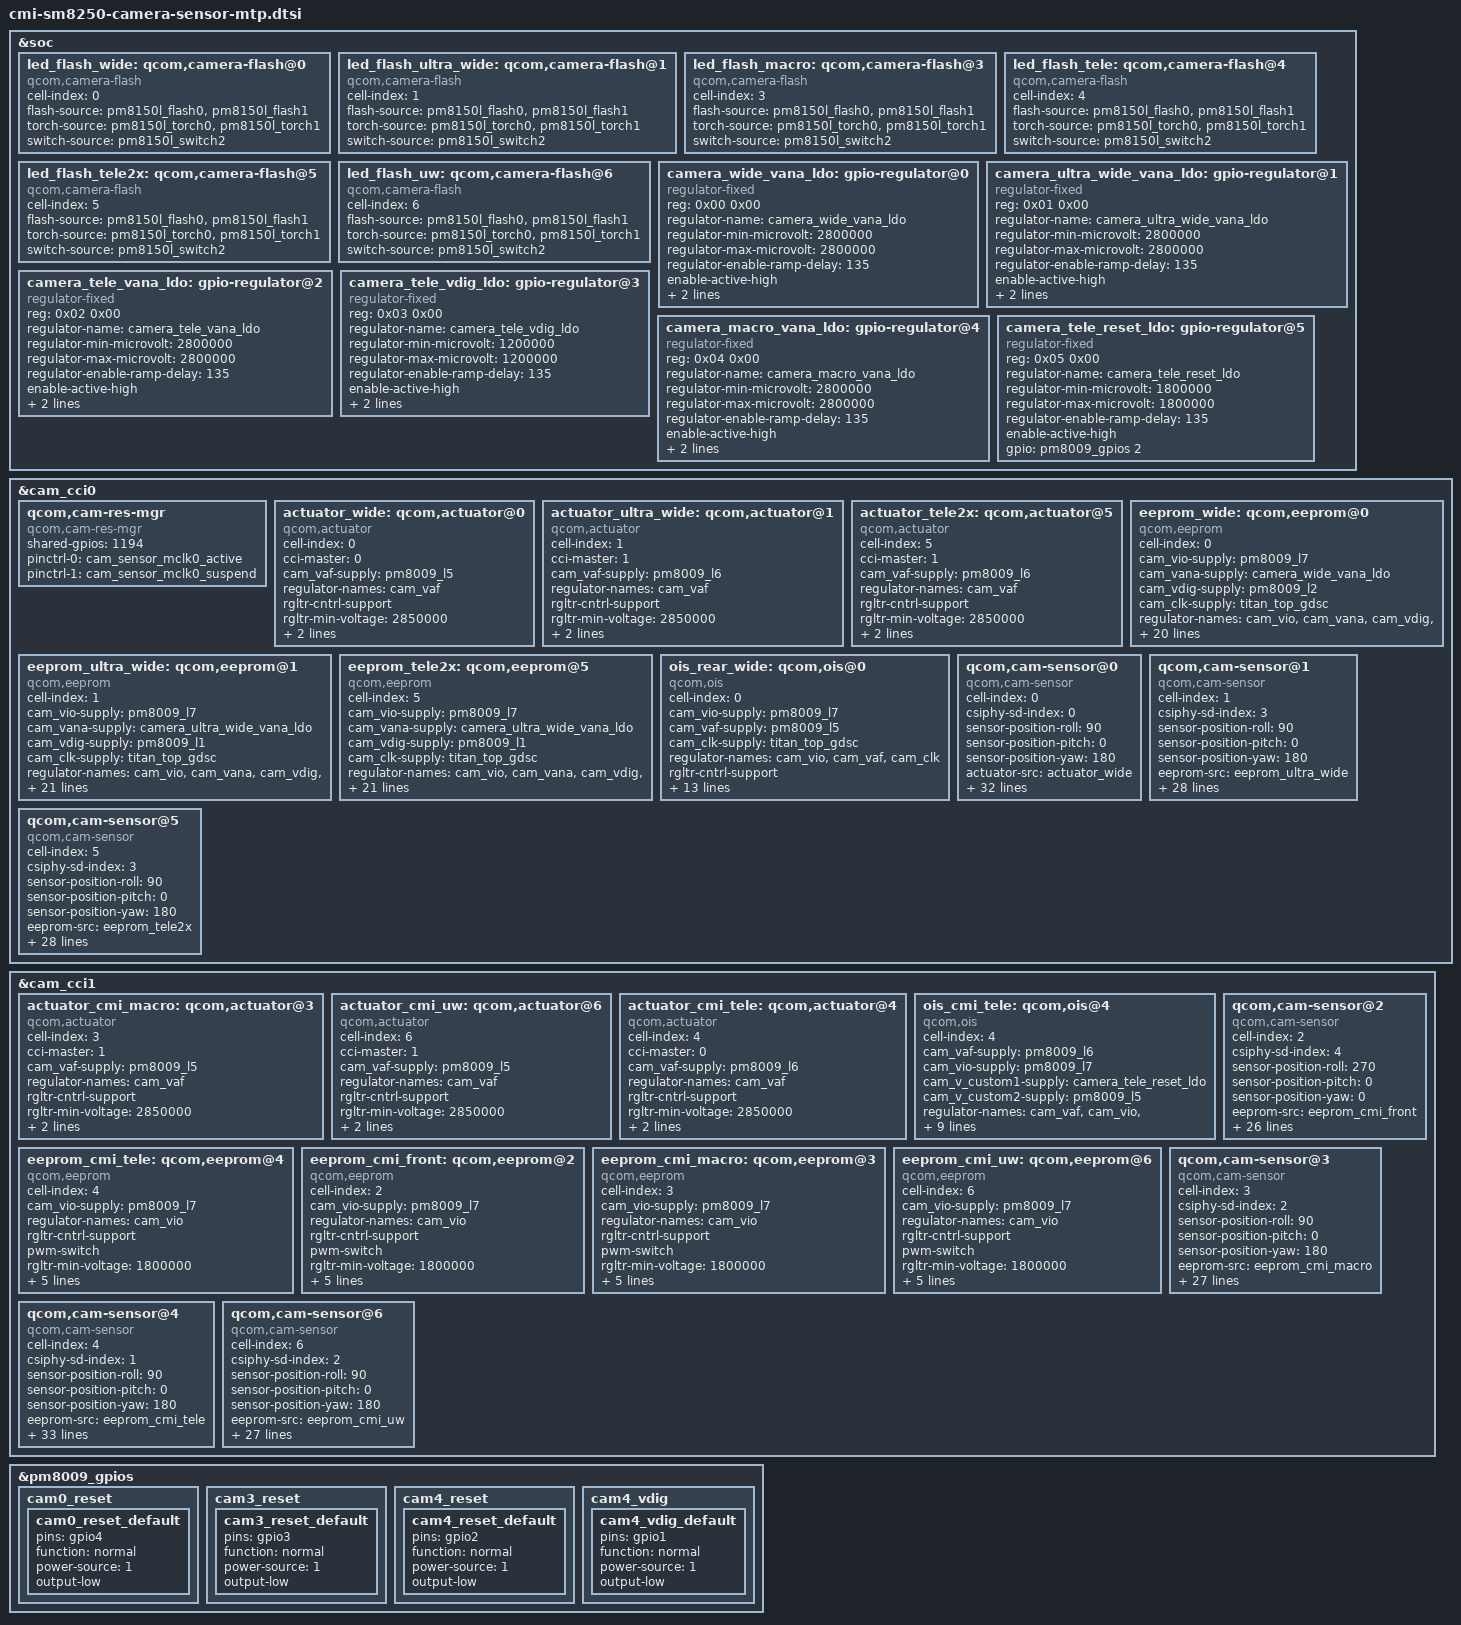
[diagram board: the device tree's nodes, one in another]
&soc {
	led_flash_wide: qcom,camera-flash@0 {
		cell-index = <0>;
		compatible = "qcom,camera-flash";
		flash-source = <&pm8150l_flash0 &pm8150l_flash1>;
		torch-source = <&pm8150l_torch0 &pm8150l_torch1>;
		switch-source = <&pm8150l_switch2>;
		status = "ok";
	};

	led_flash_ultra_wide: qcom,camera-flash@1 {
		cell-index = <1>;
		compatible = "qcom,camera-flash";
		flash-source = <&pm8150l_flash0 &pm8150l_flash1>;
		torch-source = <&pm8150l_torch0 &pm8150l_torch1>;
		switch-source = <&pm8150l_switch2>;
		status = "ok";
	};

	led_flash_macro: qcom,camera-flash@3 {
		cell-index = <3>;
		compatible = "qcom,camera-flash";
		flash-source = <&pm8150l_flash0 &pm8150l_flash1>;
		torch-source = <&pm8150l_torch0 &pm8150l_torch1>;
		switch-source = <&pm8150l_switch2>;
		status = "ok";
	};

	led_flash_tele: qcom,camera-flash@4 {
		cell-index = <4>;
		compatible = "qcom,camera-flash";
		flash-source = <&pm8150l_flash0 &pm8150l_flash1>;
		torch-source = <&pm8150l_torch0 &pm8150l_torch1>;
		switch-source = <&pm8150l_switch2>;
		status = "ok";
	};

	led_flash_tele2x: qcom,camera-flash@5 {
		cell-index = <5>;
		compatible = "qcom,camera-flash";
		flash-source = <&pm8150l_flash0 &pm8150l_flash1>;
		torch-source = <&pm8150l_torch0 &pm8150l_torch1>;
		switch-source = <&pm8150l_switch2>;
		status = "ok";
	};

	led_flash_uw: qcom,camera-flash@6 {
		cell-index = <6>;
		compatible = "qcom,camera-flash";
		flash-source = <&pm8150l_flash0 &pm8150l_flash1>;
		torch-source = <&pm8150l_torch0 &pm8150l_torch1>;
		switch-source = <&pm8150l_switch2>;
		status = "ok";
	};

	camera_wide_vana_ldo: gpio-regulator@0 {
		compatible = "regulator-fixed";
		reg = <0x00 0x00>;
		regulator-name = "camera_wide_vana_ldo";
		regulator-min-microvolt = <2800000>;
		regulator-max-microvolt = <2800000>;
		regulator-enable-ramp-delay = <135>;
		enable-active-high;
		gpio = <&pm8150l_gpios 1 0>;
		vin-supply = <&pm8150a_bob>;
	};

	camera_ultra_wide_vana_ldo: gpio-regulator@1 {
		compatible = "regulator-fixed";
		reg = <0x01 0x00>;
		regulator-name = "camera_ultra_wide_vana_ldo";
		regulator-min-microvolt = <2800000>;
		regulator-max-microvolt = <2800000>;
		regulator-enable-ramp-delay = <135>;
		enable-active-high;
		gpio = <&pm8150l_gpios 3 0>;
		vin-supply = <&pm8150a_bob>;
	};

	camera_tele_vana_ldo: gpio-regulator@2 {
		compatible = "regulator-fixed";
		reg = <0x02 0x00>;
		regulator-name = "camera_tele_vana_ldo";
		regulator-min-microvolt = <2800000>;
		regulator-max-microvolt = <2800000>;
		regulator-enable-ramp-delay = <135>;
		enable-active-high;
		gpio = <&pm8150l_gpios 4 0>;
		vin-supply = <&pm8150a_bob>;
	};

	camera_tele_vdig_ldo: gpio-regulator@3 {
		compatible = "regulator-fixed";
		reg = <0x03 0x00>;
		regulator-name = "camera_tele_vdig_ldo";
		regulator-min-microvolt = <1200000>;
		regulator-max-microvolt = <1200000>;
		regulator-enable-ramp-delay = <135>;
		enable-active-high;
		gpio = <&pm8009_gpios 1 0>;
		vin-supply = <&pm8150a_s8>;
	};

	camera_macro_vana_ldo: gpio-regulator@4 {
		compatible = "regulator-fixed";
		reg = <0x04 0x00>;
		regulator-name = "camera_macro_vana_ldo";
		regulator-min-microvolt = <2800000>;
		regulator-max-microvolt = <2800000>;
		regulator-enable-ramp-delay = <135>;
		enable-active-high;
		gpio = <&pm8150l_gpios 5 0>;
		vin-supply = <&pm8150a_bob>;
	};

	camera_tele_reset_ldo: gpio-regulator@5 {
		compatible = "regulator-fixed";
		reg = <0x05 0x00>;
		regulator-name = "camera_tele_reset_ldo";
		regulator-min-microvolt = <1800000>;
		regulator-max-microvolt = <1800000>;
		regulator-enable-ramp-delay = <135>;
		enable-active-high;
		gpio = <&pm8009_gpios 2 0>;
	};
};

&cam_cci0 {
	qcom,cam-res-mgr {
		compatible = "qcom,cam-res-mgr";
		status = "ok";
		shared-gpios = <1194>;
		pinctrl-names = "cam_res_mgr_default", "cam_res_mgr_suspend";
		pinctrl-0 = <&cam_sensor_mclk0_active>;
		pinctrl-1 = <&cam_sensor_mclk0_suspend>;
	};

	actuator_wide: qcom,actuator@0 {
		cell-index = <0>;
		compatible = "qcom,actuator";
		cci-master = <0>;
		cam_vaf-supply = <&pm8009_l5>;
		regulator-names = "cam_vaf";
		rgltr-cntrl-support;
		rgltr-min-voltage = <2850000>;
		rgltr-max-voltage = <2850000>;
		rgltr-load-current = <100000>;
	};

	actuator_ultra_wide: qcom,actuator@1 {
		cell-index = <1>;
		compatible = "qcom,actuator";
		cci-master = <1>;
		cam_vaf-supply = <&pm8009_l6>;
		regulator-names = "cam_vaf";
		rgltr-cntrl-support;
		rgltr-min-voltage = <2850000>;
		rgltr-max-voltage = <2850000>;
		rgltr-load-current = <100000>;
	};

	actuator_tele2x: qcom,actuator@5 {
		cell-index = <5>;
		compatible = "qcom,actuator";
		cci-master = <1>;
		cam_vaf-supply = <&pm8009_l6>;
		regulator-names = "cam_vaf";
		rgltr-cntrl-support;
		rgltr-min-voltage = <2850000>;
		rgltr-max-voltage = <2850000>;
		rgltr-load-current = <100000>;
	};

	eeprom_wide: qcom,eeprom@0 {
		cell-index = <0>;
		compatible = "qcom,eeprom";
		cam_vio-supply = <&pm8009_l7>;
		cam_vana-supply = <&camera_wide_vana_ldo>;
		cam_vdig-supply = <&pm8009_l2>;
		cam_clk-supply = <&titan_top_gdsc>;
		regulator-names = "cam_vio", "cam_vana", "cam_vdig",
			"cam_clk";
		rgltr-cntrl-support;
		pwm-switch;
		rgltr-min-voltage = <1800000 2800000 1104000 0>;
		rgltr-max-voltage = <1800000 2800000 1104000 0>;
		rgltr-load-current = <120000 80000 1200000 0>;
		gpio-no-mux = <0>;
		pinctrl-names = "cam_default", "cam_suspend";
		pinctrl-0 = <&cam0_reset_default>;
		pinctrl-1 = <&cam0_reset_default>;
		gpios = <&tlmm 94 0>,
			<&pm8009_gpios 4 0>;
		gpio-reset = <1>;
		gpio-req-tbl-num = <0 1>;
		gpio-req-tbl-flags = <1 0>;
		gpio-req-tbl-label = "CAMIF_MCLK0",
					"CAM_RESET0";
		sensor-mode = <0>;
		cci-master = <0>;
		status = "ok";
		use-shared-clk;
		clocks = <&clock_camcc CAM_CC_MCLK0_CLK>;
		clock-names = "cam_clk";
		clock-cntl-level = "turbo";
		clock-rates = <19200000>;
	};

	eeprom_ultra_wide: qcom,eeprom@1 {
		cell-index = <1>;
		compatible = "qcom,eeprom";
		cam_vio-supply = <&pm8009_l7>;
		cam_vana-supply = <&camera_ultra_wide_vana_ldo>;
		cam_vdig-supply = <&pm8009_l1>;
		cam_clk-supply = <&titan_top_gdsc>;
		regulator-names = "cam_vio", "cam_vana", "cam_vdig", "cam_clk";
		rgltr-cntrl-support;
		pwm-switch;
		rgltr-min-voltage = <1800000 2800000 1104000 0>;
		rgltr-max-voltage = <1800000 2800000 1104000 0>;
		rgltr-load-current = <120000 2000000 120000 0>;
		gpio-no-mux = <0>;
		pinctrl-names = "cam_default", "cam_suspend";
		pinctrl-0 = <&cam_sensor_mclk1_active
				&cam_sensor_active_rear_aux>;
		pinctrl-1 = <&cam_sensor_mclk1_suspend
				&cam_sensor_suspend_rear_aux>;
		gpios = <&tlmm 95 0>,
			<&tlmm 62 0>;
		gpio-reset = <1>;
		gpio-req-tbl-num = <0 1>;
		gpio-req-tbl-flags = <1 0>;
		gpio-req-tbl-label = "CAMIF_MCLK1",
					"CAM_RESET1";
		sensor-mode = <0>;
		cci-master = <1>;
		status = "ok";
		clocks = <&clock_camcc CAM_CC_MCLK1_CLK>;
		clock-names = "cam_clk";
		clock-cntl-level = "turbo";
		clock-rates = <19200000>;
	};

	eeprom_tele2x: qcom,eeprom@5 {
		cell-index = <5>;
		compatible = "qcom,eeprom";
		cam_vio-supply = <&pm8009_l7>;
		cam_vana-supply = <&camera_ultra_wide_vana_ldo>;
		cam_vdig-supply = <&pm8009_l1>;
		cam_clk-supply = <&titan_top_gdsc>;
		regulator-names = "cam_vio", "cam_vana", "cam_vdig", "cam_clk";
		rgltr-cntrl-support;
		pwm-switch;
		rgltr-min-voltage = <1800000 2800000 1104000 0>;
		rgltr-max-voltage = <1800000 2800000 1104000 0>;
		rgltr-load-current = <120000 2000000 120000 0>;
		gpio-no-mux = <0>;
		pinctrl-names = "cam_default", "cam_suspend";
		pinctrl-0 = <&cam_sensor_mclk1_active
				&cam_sensor_active_rear_aux>;
		pinctrl-1 = <&cam_sensor_mclk1_suspend
				&cam_sensor_suspend_rear_aux>;
		gpios = <&tlmm 95 0>,
			<&tlmm 62 0>;
		gpio-reset = <1>;
		gpio-req-tbl-num = <0 1>;
		gpio-req-tbl-flags = <1 0>;
		gpio-req-tbl-label = "CAMIF_MCLK1",
					"CAM_RESET1";
		sensor-mode = <0>;
		cci-master = <1>;
		status = "ok";
		clocks = <&clock_camcc CAM_CC_MCLK1_CLK>;
		clock-names = "cam_clk";
		clock-cntl-level = "turbo";
		clock-rates = <19200000>;
	};

	ois_rear_wide: qcom,ois@0 {
		cell-index = <0>;
		compatible = "qcom,ois";
		cam_vio-supply = <&pm8009_l7>;
		cam_vaf-supply = <&pm8009_l5>;
		cam_clk-supply = <&titan_top_gdsc>;
		regulator-names = "cam_vio", "cam_vaf", "cam_clk";
		rgltr-cntrl-support;
		rgltr-min-voltage = <1800000 2850000 0>;
		rgltr-max-voltage = <1800000 2850000 0>;
		rgltr-load-current = <120000 100000 0>;
		gpio-no-mux = <0>;
		gpios = <&tlmm 94 0>;
		gpio-req-tbl-num = <0>;
		gpio-req-tbl-flags = <1>;
		gpio-req-tbl-label = "CAMIF_MCLK0";
		cci-master = <0>;
		status = "ok";
		use-shared-clk;
		clocks = <&clock_camcc CAM_CC_MCLK0_CLK>;
		clock-names = "cam_clk";
		clock-cntl-level = "turbo";
		clock-rates = <19200000>;
	};


	/*  J1 Wide sensor */
	qcom,cam-sensor@0 {
		cell-index = <0>;
		compatible = "qcom,cam-sensor";
		csiphy-sd-index = <0>;
		sensor-position-roll = <90>;
		sensor-position-pitch = <0>;
		sensor-position-yaw = <180>;
		actuator-src = <&actuator_wide>;
		led-flash-src = <&led_flash_wide>;
		eeprom-src = <&eeprom_wide>;
		ois-src = <&ois_rear_wide>;
		cam_vio-supply = <&pm8009_l7>;
		cam_vana-supply = <&camera_wide_vana_ldo>;
		cam_vdig-supply = <&pm8009_l2>;
		cam_vaf-supply = <&pm8009_l5>;
		cam_clk-supply = <&titan_top_gdsc>;
		regulator-names = "cam_vio", "cam_vana", "cam_vdig",
			"cam_vaf", "cam_clk";
		rgltr-cntrl-support;
		pwm-switch;
		rgltr-min-voltage = <1800000 2800000 1104000 2850000 0>;
		rgltr-max-voltage = <1800000 2800000 1104000 2850000 0>;
		rgltr-load-current = <120000 80000 1200000 100000 0>;
		gpio-no-mux = <0>;
		pinctrl-names = "cam_default", "cam_suspend";
		pinctrl-0 = <&cam0_reset_default>;
		pinctrl-1 = <&cam0_reset_default>;
		gpios = <&tlmm 94 0>,
			<&pm8009_gpios 4 0>;
		gpio-reset = <1>;
		gpio-req-tbl-num = <0 1>;
		gpio-req-tbl-flags = <1 0>;
		gpio-req-tbl-label = "CAMIF_MCLK0",
					"CAM_RESET0";
		sensor-mode = <0>;
		cci-master = <0>;
		status = "ok";
		use-shared-clk;
		clocks = <&clock_camcc CAM_CC_MCLK0_CLK>;
		clock-names = "cam_clk";
		clock-cntl-level = "turbo";
		clock-rates = <19200000>;
	};

	/*  J1 Ultra Wide sensor */
	qcom,cam-sensor@1 {
		cell-index = <1>;
		compatible = "qcom,cam-sensor";
		csiphy-sd-index = <3>;
		sensor-position-roll = <90>;
		sensor-position-pitch = <0>;
		sensor-position-yaw = <180>;
		eeprom-src = <&eeprom_ultra_wide>;
		led-flash-src = <&led_flash_ultra_wide>;
		actuator-src = <&actuator_ultra_wide>;
		cam_vio-supply = <&pm8009_l7>;
		cam_vana-supply = <&camera_ultra_wide_vana_ldo>;
		cam_vdig-supply = <&pm8009_l1>;
		cam_clk-supply = <&titan_top_gdsc>;
		regulator-names = "cam_vio", "cam_vana", "cam_vdig", "cam_clk";
		rgltr-cntrl-support;
		pwm-switch;
		rgltr-min-voltage = <1800000 2800000 1104000 0>;
		rgltr-max-voltage = <1800000 2800000 1104000 0>;
		rgltr-load-current = <120000 2000000 120000 0>;
		gpio-no-mux = <0>;
		pinctrl-names = "cam_default", "cam_suspend";
		pinctrl-0 = <&cam_sensor_mclk1_active
				&cam_sensor_active_rear_aux>;
		pinctrl-1 = <&cam_sensor_mclk1_suspend
				&cam_sensor_suspend_rear_aux>;
		gpios = <&tlmm 95 0>,
			<&tlmm 62 0>;
		gpio-reset = <1>;
		gpio-req-tbl-num = <0 1>;
		gpio-req-tbl-flags = <1 0>;
		gpio-req-tbl-label = "CAMIF_MCLK1",
					"CAM_RESET1";
		sensor-mode = <0>;
		cci-master = <1>;
		status = "ok";
		clocks = <&clock_camcc CAM_CC_MCLK1_CLK>;
		clock-names = "cam_clk";
		clock-cntl-level = "turbo";
		clock-rates = <19200000>;
	};

	/*  J1 Tele2x s5k2l7 */
	qcom,cam-sensor@5 {
		cell-index = <5>;
		compatible = "qcom,cam-sensor";
		csiphy-sd-index = <3>;
		sensor-position-roll = <90>;
		sensor-position-pitch = <0>;
		sensor-position-yaw = <180>;
		eeprom-src = <&eeprom_tele2x>;
		led-flash-src = <&led_flash_tele2x>;
		actuator-src = <&actuator_tele2x>;
		cam_vio-supply = <&pm8009_l7>;
		cam_vana-supply = <&camera_ultra_wide_vana_ldo>;
		cam_vdig-supply = <&pm8009_l1>;
		cam_clk-supply = <&titan_top_gdsc>;
		regulator-names = "cam_vio", "cam_vana", "cam_vdig", "cam_clk";
		rgltr-cntrl-support;
		pwm-switch;
		rgltr-min-voltage = <1800000 2800000 1104000 0>;
		rgltr-max-voltage = <1800000 2800000 1104000 0>;
		rgltr-load-current = <120000 2000000 120000 0>;
		gpio-no-mux = <0>;
		pinctrl-names = "cam_default", "cam_suspend";
		pinctrl-0 = <&cam_sensor_mclk1_active
				&cam_sensor_active_rear_aux>;
		pinctrl-1 = <&cam_sensor_mclk1_suspend
				&cam_sensor_suspend_rear_aux>;
		gpios = <&tlmm 95 0>,
			<&tlmm 62 0>;
		gpio-reset = <1>;
		gpio-req-tbl-num = <0 1>;
		gpio-req-tbl-flags = <1 0>;
		gpio-req-tbl-label = "CAMIF_MCLK1",
					"CAM_RESET1";
		sensor-mode = <0>;
		cci-master = <1>;
		status = "ok";
		clocks = <&clock_camcc CAM_CC_MCLK1_CLK>;
		clock-names = "cam_clk";
		clock-cntl-level = "turbo";
		clock-rates = <19200000>;
	};
};

&cam_cci1 {
	/*  J1 macro actuator */
	actuator_cmi_macro: qcom,actuator@3 {
		cell-index = <3>;
		compatible = "qcom,actuator";
		cci-master = <1>;
		cam_vaf-supply = <&pm8009_l5>;
		regulator-names = "cam_vaf";
		rgltr-cntrl-support;
		rgltr-min-voltage = <2850000>;
		rgltr-max-voltage = <2850000>;
		rgltr-load-current = <100000>;
	};

	/*  J1 uw actuator */
	actuator_cmi_uw: qcom,actuator@6 {
		cell-index = <6>;
		compatible = "qcom,actuator";
		cci-master = <1>;
		cam_vaf-supply = <&pm8009_l5>;
		regulator-names = "cam_vaf";
		rgltr-cntrl-support;
		rgltr-min-voltage = <2850000>;
		rgltr-max-voltage = <2850000>;
		rgltr-load-current = <100000>;
	};

	/*  J1 tele actuator  */
	actuator_cmi_tele: qcom,actuator@4 {
		cell-index = <4>;
		compatible = "qcom,actuator";
		cci-master = <0>;
		cam_vaf-supply = <&pm8009_l6>;
		regulator-names = "cam_vaf";
		rgltr-cntrl-support;
		rgltr-min-voltage = <2850000>;
		rgltr-max-voltage = <2850000>;
		rgltr-load-current = <100000>;
	};

	/*  J1 tele ois  */
	ois_cmi_tele: qcom,ois@4 {
		cell-index = <4>;
		compatible = "qcom,ois";
		cam_vaf-supply = <&pm8009_l6>;
		cam_vio-supply = <&pm8009_l7>;
		cam_v_custom1-supply = <&camera_tele_reset_ldo>;
		cam_v_custom2-supply = <&pm8009_l5>;
		regulator-names = "cam_vaf", "cam_vio", "cam_v_custom1", "cam_v_custom2";
		rgltr-cntrl-support;
		rgltr-min-voltage = <2850000 1800000 1800000 2850000>;
		rgltr-max-voltage = <2850000 1800000 1800000 2850000>;
		rgltr-load-current = <100000 120000 120000 100000>;
		cci-master = <0>;
	};

	/*  J1 tele eeprom  */
	eeprom_cmi_tele: qcom,eeprom@4 {
		cell-index = <4>;
		compatible = "qcom,eeprom";
		cam_vio-supply = <&pm8009_l7>;
		regulator-names = "cam_vio";
		rgltr-cntrl-support;
		pwm-switch;
		rgltr-min-voltage = <1800000>;
		rgltr-max-voltage = <1800000>;
		rgltr-load-current = <120000>;
		gpio-no-mux = <0>;
		sensor-mode = <0>;
		cci-master = <0>;
		status = "ok";
	};

	/*  J1 front eeprom */
	eeprom_cmi_front: qcom,eeprom@2 {
		cell-index = <2>;
		compatible = "qcom,eeprom";
		cam_vio-supply = <&pm8009_l7>;
		regulator-names = "cam_vio";
		rgltr-cntrl-support;
		pwm-switch;
		rgltr-min-voltage = <1800000>;
		rgltr-max-voltage = <1800000>;
		rgltr-load-current = <120000>;
		gpio-no-mux = <0>;
		sensor-mode = <0>;
		cci-master = <0>;
		status = "ok";
	};

	/*  J1 macro eeprom  */
	eeprom_cmi_macro: qcom,eeprom@3 {
		cell-index = <3>;
		compatible = "qcom,eeprom";
		cam_vio-supply = <&pm8009_l7>;
		regulator-names = "cam_vio";
		rgltr-cntrl-support;
		pwm-switch;
		rgltr-min-voltage = <1800000>;
		rgltr-max-voltage = <1800000>;
		rgltr-load-current = <120000>;
		gpio-no-mux = <0>;
		sensor-mode = <0>;
		cci-master = <1>;
		status = "ok";
	};

	/*  J1 uw eeprom  */
	eeprom_cmi_uw: qcom,eeprom@6 {
		cell-index = <6>;
		compatible = "qcom,eeprom";
		cam_vio-supply = <&pm8009_l7>;
		regulator-names = "cam_vio";
		rgltr-cntrl-support;
		pwm-switch;
		rgltr-min-voltage = <1800000>;
		rgltr-max-voltage = <1800000>;
		rgltr-load-current = <120000>;
		gpio-no-mux = <0>;
		sensor-mode = <0>;
		cci-master = <1>;
		status = "ok";
	};

	/*  J1 Front sensor */
	qcom,cam-sensor@2 {
		cell-index = <2>;
		compatible = "qcom,cam-sensor";
		csiphy-sd-index = <4>;
		sensor-position-roll = <270>;
		sensor-position-pitch = <0>;
		sensor-position-yaw = <0>;
		eeprom-src = <&eeprom_cmi_front>;
		cam_vio-supply = <&pm8009_l7>;
		cam_vana-supply = <&camera_tele_vana_ldo>;
		cam_vdig-supply = <&pm8009_l4>;
		cam_clk-supply = <&titan_top_gdsc>;
		regulator-names = "cam_vio", "cam_vana", "cam_vdig",
			"cam_clk";
		rgltr-cntrl-support;
		pwm-switch;
		rgltr-min-voltage = <1800000 2800000 1104000 0>;
		rgltr-max-voltage = <1800000 2800000 1104000 0>;
		rgltr-load-current = <120000 80000 120000 0>;
		gpio-no-mux = <0>;
		pinctrl-names = "cam_default", "cam_suspend";
		pinctrl-0 = <&cam_sensor_mclk4_active
				 &cam_sensor_active_3>;
		pinctrl-1 = <&cam_sensor_mclk4_suspend
				 &cam_sensor_suspend_3>;
		gpios = <&tlmm 98 0>,
			<&tlmm 109 0>;
		gpio-reset = <1>;
		gpio-req-tbl-num = <0 1>;
		gpio-req-tbl-flags = <1 0>;
		gpio-req-tbl-label = "CAMIF_MCLK4",
					"CAM_RESET4";
		sensor-mode = <0>;
		cci-master = <0>;
		status = "ok";
		clocks = <&clock_camcc CAM_CC_MCLK4_CLK>;
		clock-names = "cam_clk";
		clock-cntl-level = "turbo";
		clock-rates = <19200000>;
	};

	/*  J1 Macro sensor  */
	qcom,cam-sensor@3 {
		cell-index = <3>;
		compatible = "qcom,cam-sensor";
		csiphy-sd-index = <2>;
		sensor-position-roll = <90>;
		sensor-position-pitch = <0>;
		sensor-position-yaw = <180>;
		eeprom-src = <&eeprom_cmi_macro>;
		actuator-src = <&actuator_cmi_macro>;
		led-flash-src = <&led_flash_macro>;
		cam_vana-supply = <&camera_macro_vana_ldo>;
		cam_vio-supply = <&pm8009_l7>;
		cam_vdig-supply = <&pm8009_l3>;
		cam_clk-supply = <&titan_top_gdsc>;
		regulator-names = "cam_vio", "cam_vdig",
			"cam_clk","cam_vana";
		rgltr-cntrl-support;
		rgltr-min-voltage = <1800000 1200000 0 2800000>;
		rgltr-max-voltage = <1800000 1200000 0 2800000>;
		rgltr-load-current = <120000 1056000 0 80000>;
		gpio-no-mux = <0>;
		pinctrl-names = "cam_default", "cam_suspend";
		pinctrl-0 = <&cam_sensor_mclk3_active
			     &cam3_reset_default>;
		pinctrl-1 = <&cam_sensor_mclk3_suspend
			     &cam3_reset_default>;
		gpios = <&tlmm 97 0>,
			<&pm8009_gpios 3 0>;
		gpio-reset = <1>;
		gpio-req-tbl-num = <0 1>;
		gpio-req-tbl-flags = <1 0>;
		gpio-req-tbl-label = "CAMIF_MCLK3",
					"CAM_RESET3";
		sensor-mode = <0>;
		cci-master = <1>;
		status = "ok";
		clocks = <&clock_camcc CAM_CC_MCLK3_CLK>;
		clock-names = "cam_clk";
		clock-cntl-level = "turbo";
		clock-rates = <19200000>;
	};

	/*  J1 Tele sensor  */
	qcom,cam-sensor@4 {
		cell-index = <4>;
		compatible = "qcom,cam-sensor";
		csiphy-sd-index = <1>;
		sensor-position-roll = <90>;
		sensor-position-pitch = <0>;
		sensor-position-yaw = <180>;
		eeprom-src = <&eeprom_cmi_tele>;
		led-flash-src = <&led_flash_tele>;
		actuator-src = <&actuator_cmi_tele>;
		ois-src = <&ois_cmi_tele>;
		cam_vio-supply = <&pm8009_l7>;
		cam_vana-supply = <&camera_tele_vana_ldo>;
		cam_vdig-supply = <&camera_tele_vdig_ldo>;
		cam_vaf-supply = <&pm8009_l6>;
		cam_clk-supply = <&titan_top_gdsc>;
		cam_v_custom1-supply = <&camera_tele_reset_ldo>;
		regulator-names = "cam_vio", "cam_vana", "cam_vdig",
			"cam_vaf", "cam_clk", "cam_v_custom1";
		rgltr-cntrl-support;
		pwm-switch;
		rgltr-min-voltage = <1800000 2800000 1200000 2850000 0 1800000>;
		rgltr-max-voltage = <1800000 2800000 1200000 2850000 0 1800000>;
		rgltr-load-current = <120000 80000 1200000 100000 0 120000>;
		gpio-no-mux = <0>;
		pinctrl-names = "cam_default", "cam_suspend";
		pinctrl-0 = <&cam_sensor_mclk2_active
				&cam4_reset_default
				&cam4_vdig_default>;
		pinctrl-1 = <&cam_sensor_mclk2_suspend
				&cam4_reset_default
				&cam4_vdig_default>;
		gpios = <&tlmm 96 0>;
		gpio-req-tbl-num = <0>;
		gpio-req-tbl-flags = <1>;
		gpio-req-tbl-label = "CAMIF_MCLK2";
		sensor-mode = <0>;
		cci-master = <0>;
		status = "ok";
		clocks = <&clock_camcc CAM_CC_MCLK2_CLK>;
		clock-names = "cam_clk";
		clock-cntl-level = "turbo";
		clock-rates = <19200000>;
	};

	/*  J1 UW imx350  */
	qcom,cam-sensor@6 {
		cell-index = <6>;
		compatible = "qcom,cam-sensor";
		csiphy-sd-index = <2>;
		sensor-position-roll = <90>;
		sensor-position-pitch = <0>;
		sensor-position-yaw = <180>;
		eeprom-src = <&eeprom_cmi_uw>;
		actuator-src = <&actuator_cmi_uw>;
		led-flash-src = <&led_flash_uw>;
		cam_vana-supply = <&camera_macro_vana_ldo>;
		cam_vio-supply = <&pm8009_l7>;
		cam_vdig-supply = <&pm8009_l3>;
		cam_clk-supply = <&titan_top_gdsc>;
		regulator-names = "cam_vio", "cam_vdig",
			"cam_clk","cam_vana";
		rgltr-cntrl-support;
		rgltr-min-voltage = <1800000 1100000 0 2800000>;
		rgltr-max-voltage = <1800000 1100000 0 2800000>;
		rgltr-load-current = <120000 1056000 0 80000>;
		gpio-no-mux = <0>;
		pinctrl-names = "cam_default", "cam_suspend";
		pinctrl-0 = <&cam_sensor_mclk3_active
			     &cam3_reset_default>;
		pinctrl-1 = <&cam_sensor_mclk3_suspend
			     &cam3_reset_default>;
		gpios = <&tlmm 97 0>,
			<&pm8009_gpios 3 0>;
		gpio-reset = <1>;
		gpio-req-tbl-num = <0 1>;
		gpio-req-tbl-flags = <1 0>;
		gpio-req-tbl-label = "CAMIF_MCLK3",
					"CAM_RESET3";
		sensor-mode = <0>;
		cci-master = <1>;
		status = "ok";
		clocks = <&clock_camcc CAM_CC_MCLK3_CLK>;
		clock-names = "cam_clk";
		clock-cntl-level = "turbo";
		clock-rates = <19200000>;
	};
};

&pm8009_gpios {
	cam0_reset {
		cam0_reset_default: cam0_reset_default {
			pins = "gpio4";
			function = "normal";
			power-source = <1>;
			output-low;
		};
	};

	cam3_reset {
		cam3_reset_default: cam3_reset_default {
			pins = "gpio3";
			function = "normal";
			power-source = <1>;
			output-low;
		};
	};

	cam4_reset {
		cam4_reset_default: cam4_reset_default {
			pins = "gpio2";
			function = "normal";
			power-source = <1>;
			output-low;
		};
	};

	cam4_vdig {
		cam4_vdig_default: cam4_vdig_default {
			pins = "gpio1";
			function = "normal";
			power-source = <1>;
			output-low;
		};
	};
};
